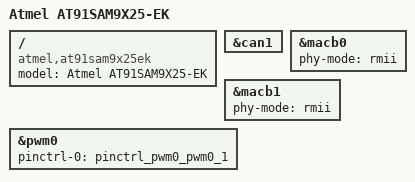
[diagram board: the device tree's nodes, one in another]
// SPDX-License-Identifier: GPL-2.0-or-later
/*
 * at91sam9x25ek.dts - Device Tree file for AT91SAM9X25-EK board
 *
 *  Copyright (C) 2012 Atmel,
 *                2012 Nicolas Ferre <nicolas.ferre@atmel.com>
 */
/dts-v1/;
#include "at91sam9x25.dtsi"
#include "at91sam9x5ek.dtsi"

/ {
	model = "Atmel AT91SAM9X25-EK";
	compatible = "atmel,at91sam9x25ek", "atmel,at91sam9x5ek", "atmel,at91sam9x5", "atmel,at91sam9";
};

&can1 {
	status = "okay";
};

&macb0 {
	phy-mode = "rmii";
	status = "okay";
};

&macb1 {
	phy-mode = "rmii";
	status = "okay";
};

&pwm0 {
	pinctrl-names = "default";
	pinctrl-0 = <&pinctrl_pwm0_pwm0_1>;
	status = "okay";
};
